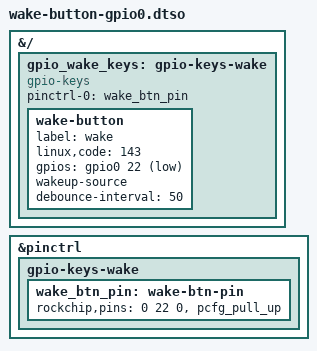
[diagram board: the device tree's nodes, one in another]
// SPDX-License-Identifier: BSD-3-Clause
/*
 * Wake push-button on Radxa CM3 (RK3566) / CM4IO 40-pin header PIN 33.
 *
 * PIN 33 = BCM GPIO13 (schematic net) = Rockchip GPIO0_C6 = gpiochip0 line 22
 * (confirmed via /sys/kernel/debug/gpio: "gpio-22 (PIN_33)"). GPIO0 is the
 * PMU/always-on bank — the ONLY GPIO bank kept powered in deep suspend (mem/STR)
 * on RK3566, so it can actually wake the SoC. A button on GPIO1..4 would NOT wake.
 * (Earlier this was on phys pin 13 = GPIO0_B7 = BCM27/"D27" — wrong pin; the
 * schematic's "GPIO13" is BCM numbering = physical pin 33.)
 *
 * BENCH-TEST wiring: momentary button (or alligator lead) from header pin 33 to GND.
 * Idles HIGH via the internal pull-up below (RK_PC6 + pcfg_pull_up); pulling it LOW
 * -> KEY_WAKEUP. KEY_WAKEUP (143) rather than KEY_POWER so a press while awake is NOT
 * treated by logind as a shutdown request — it only resumes from STR.
 * NOTE (production IGN_SENSE): if pin 33 becomes the ignition-sense input (high=ign-on),
 * flip to active-HIGH + pull-DOWN so the wake fires on the ign-ON rising edge, and add a
 * userspace watcher that runs `systemctl suspend` on the ign-OFF edge. Measure the real
 * level through the HAT Block A front-end first (it may invert).
 *
 * Stack this with the CAN + DSI overlays when pre-merging into the base DTB:
 *   fdtoverlay -i base.orig -o both.dtb mcp2515-2ch-hatplus.dtbo \
 *              waveshare-12in3-dsi1.dtbo wake-button-gpio0.dtbo
 * (U-Boot fdtoverlays apply traps into rescue on this board — always pre-merge.)
 */
/dts-v1/;
/plugin/;

&{/} {
	gpio_wake_keys: gpio-keys-wake {
		compatible = "gpio-keys";
		pinctrl-names = "default";
		pinctrl-0 = <&wake_btn_pin>;

		wake-button {
			label = "wake";
			linux,code = <143>;		/* KEY_WAKEUP */
			gpios = <&gpio0 22 1>;		/* GPIO0_C6 (hdr pin 33), GPIO_ACTIVE_LOW */
			wakeup-source;
			debounce-interval = <50>;
		};
	};
};

&pinctrl {
	gpio-keys-wake {
		wake_btn_pin: wake-btn-pin {
			/* bank 0, RK_PC6 (=22), func GPIO (0), internal pull-up.
			   pcfg_pull_up is a base-DTB symbol (resolved by fdtoverlay). */
			rockchip,pins = <0 22 0 &pcfg_pull_up>;
		};
	};
};
